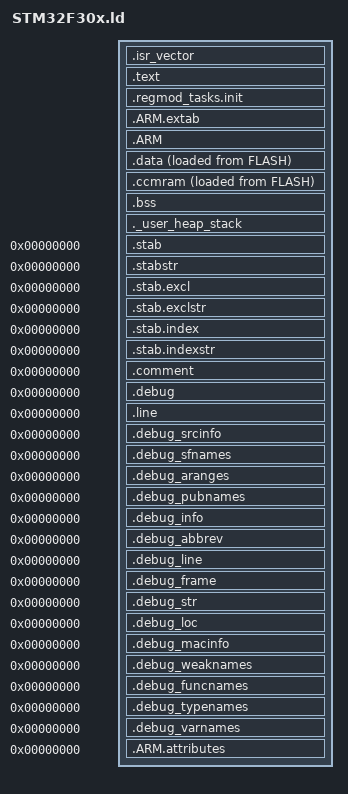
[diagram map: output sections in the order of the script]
/**
 ******************************************************************************
 * @file    STM32F30x.ld
 * @author  Philippose Rajan
 * @date    09-November-2013
 * @brief   Linker Script for the STM32F303VCT6 Cortex-M4F Controller
 * @see	    The GNU Public License (GPL) Version 3
 *
 ******************************************************************************
 */
/*
 * This program is free software; you can redistribute it and/or modify
 * it under the terms of the GNU General Public License as published by
 * the Free Software Foundation; either version 3 of the License, or
 * (at your option) any later version.
 *
 * This program is distributed in the hope that it will be useful, but
 * WITHOUT ANY WARRANTY; without even the implied warranty of MERCHANTABILITY
 * or FITNESS FOR A PARTICULAR PURPOSE. See the GNU General Public License
 * for more details.
 *
 * You should have received a copy of the GNU General Public License along
 * with this program; if not, write to the Free Software Foundation, Inc.,
 * 59 Temple Place, Suite 330, Boston, MA 02111-1307 USA
 */



/* Include the Linker file specifying the Memory Layout */
INCLUDE STM32F30x_MemLayout.ld

/* Include the Linker File specifying the required Heap and Stack Sizes */
INCLUDE STM32F30x_Heap_Stack.ld



/* Specify the Entry Point after a Reset */
ENTRY(Reset_Handler)

/* Highest address of the user mode stack (Usually end of RAM) */
_stack_end = ORIGIN(RAM) + LENGTH(RAM);



/* Define output sections */
SECTIONS
{
  /* The startup code goes first into FLASH */
  .isr_vector :
  {
    . = ALIGN(4);
    KEEP(*(.isr_vector)) /* Startup code */
    . = ALIGN(4);
  } >FLASH


  /* The program code and other data goes into FLASH */
  .text :
  {
    . = ALIGN(4);
    *(.text)           /* .text sections (code) */
    *(.text*)          /* .text* sections (code) */
    *(.rodata)         /* .rodata sections (constants, strings, etc.) */
    *(.rodata*)        /* .rodata* sections (constants, strings, etc.) */
    *(.glue_7)         /* glue arm to thumb code (Probably not required...) */
    *(.glue_7t)        /* glue thumb to arm code (Probably not required...) */
    *(.eh_frame)

    KEEP (*(.init))
    KEEP (*(.fini))

    . = ALIGN(4);
    _etext = .;        /* define a global symbols at end of code */
  } >FLASH
  
  
  
  /* Modules / Tasks go into this section */
  .regmod_tasks.init :
  {
    . = ALIGN(4);
    __reg_mod_tasks_start = .;
    KEEP (*(.regmod_tasks.init))
    . = ALIGN(4);
    __reg_mod_tasks_end = .;
  } >FLASH
 


  /* Exception Handling sections */
  .ARM.extab : 
  { 
    *(.ARM.extab* .gnu.linkonce.armextab.*) 
  } >FLASH
  
  
  .ARM : 
  {
    __exidx_start = .;
    *(.ARM.exidx*)
    __exidx_end = .;
  } >FLASH


  /* used by the startup to initialize data */
  _sidata = LOADADDR(.data);

  /* Initialized data sections goes into RAM, load LMA copy after code */
  .data :
  {
    . = ALIGN(4);
    _sdata = .;        /* create a global symbol at data start */
    *(.data)           /* .data sections */
    *(.data*)          /* .data* sections */

    . = ALIGN(4);
    _edata = .;        /* define a global symbol at data end */
  } >RAM AT> FLASH
  
  
  _siccmram = LOADADDR(.ccmram);

  /* CCM-RAM section 
  * 
  * IMPORTANT NOTE! 
  * If initialized variables will be placed in this section, 
  * the startup code needs to be modified to copy the init-values.  
  */
  .ccmram : 
  {
    . = ALIGN(4);
    _sccmram = .;       /* create a global symbol at ccmram start */
    *(.ccmram)
    *(.ccmram*)
    
    . = ALIGN(4);
    _eccmram = .;       /* create a global symbol at ccmram end */
  } >CCMRAM AT> FLASH


  /* Uninitialized data section */
  . = ALIGN(4);
  .bss (NOLOAD) :
  {
    /* This is used by the startup in order to initialize the .bss secion */
    _sbss = .;         /* define a global symbol at bss start */
    __bss_start__ = _sbss;
    *(.bss)
    *(.bss*)
    *(COMMON)
    . = ALIGN(4);
    _ebss = .;         /* define a global symbol at bss end */
    __bss_end__ = _ebss;
  } >RAM


  /* User_heap_stack section, used to check that there is enough RAM left */
  ._user_heap_stack (NOLOAD) :
  {
    . = ALIGN(4);
    PROVIDE ( end = . );
    PROVIDE ( _end = . );
    . = . + _Heap_Size;
    . = . + _Stack_Size;
    . = ALIGN(4);
  } >RAM


  /* Stabs debugging sections. */
  .stab 0 : { *(.stab) }
  .stabstr 0 : { *(.stabstr) }
  .stab.excl 0 : { *(.stab.excl) }
  .stab.exclstr 0 : { *(.stab.exclstr) }
  .stab.index 0 : { *(.stab.index) }
  .stab.indexstr 0 : { *(.stab.indexstr) }
  .comment 0 : { *(.comment) }
  /* DWARF debug sections.
     Symbols in the DWARF debugging sections are relative to the beginning
     of the section so we begin them at 0. */
  /* DWARF 1 */
  .debug 0 : { *(.debug) }
  .line 0 : { *(.line) }
  /* GNU DWARF 1 extensions */
  .debug_srcinfo 0 : { *(.debug_srcinfo) }
  .debug_sfnames 0 : { *(.debug_sfnames) }
  /* DWARF 1.1 and DWARF 2 */
  .debug_aranges 0 : { *(.debug_aranges) }
  .debug_pubnames 0 : { *(.debug_pubnames) }
  /* DWARF 2 */
  .debug_info 0 : { *(.debug_info .gnu.linkonce.wi.*) }
  .debug_abbrev 0 : { *(.debug_abbrev) }
  .debug_line 0 : { *(.debug_line) }
  .debug_frame 0 : { *(.debug_frame) }
  .debug_str 0 : { *(.debug_str) }
  .debug_loc 0 : { *(.debug_loc) }
  .debug_macinfo 0 : { *(.debug_macinfo) }
  /* SGI/MIPS DWARF 2 extensions */
  .debug_weaknames 0 : { *(.debug_weaknames) }
  .debug_funcnames 0 : { *(.debug_funcnames) }
  .debug_typenames 0 : { *(.debug_typenames) }
  .debug_varnames 0 : { *(.debug_varnames) }


  /* Remove information from the standard libraries */
  /DISCARD/ :
  {
    libc.a ( * )
    libm.a ( * )
    libgcc.a ( * )
  }


  .ARM.attributes 0 : { *(.ARM.attributes) }
}
